# AON_WUC register map
Vendor: Texas Instruments
Peripheral module from a debugger description file (folder CC26x0R2F).
Registers are 32-bit, access per field, reset 0x0 unless marked. A register's access mark holds for its fields unless they carry their own. Offsets are as the file gives them; lines under a group give offsets from that group; [hi:lo] are bit positions; {n}, {i} and the like mark numbered series; 'fields as' and 'values as' point back to an identical list; <NAME> marks a mode.

## AON_WUC — This component control the Wakeup controller residing in the AON domain. Note: This module is only supporting 32 bit ReadWrite access from MCU
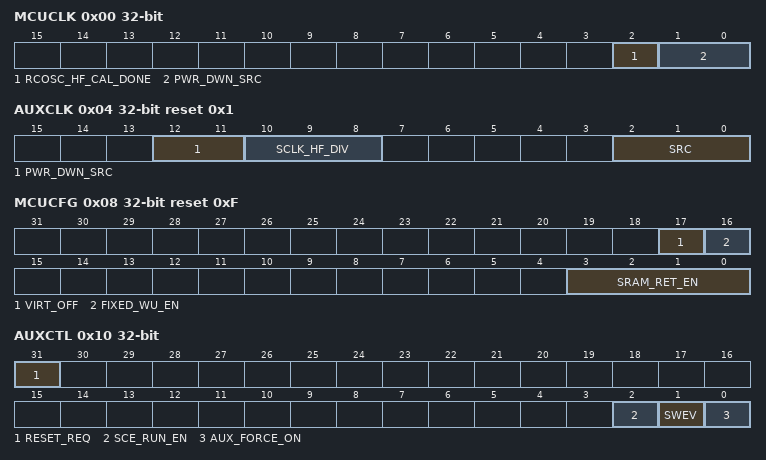
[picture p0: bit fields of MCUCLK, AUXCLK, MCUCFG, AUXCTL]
0x00 MCUCLK — MCU Clock Management This register contains bitfields related to the MCU clock.
  [2] RCOSC_HF_CAL_DONE rw — MCU bootcode will set this bit when RCOSC_HF is calibrated. The FLASH can not be used until this bit is set. 1: RCOSC_HF is calibrated to 48 MHz, allowing FLASH to power up. 0: RCOSC_HF is not yet calibrated, ie FLASH must not assume that the SCLK_HF is safe
  [1:0] PWR_DWN_SRC rw — Controls the clock source for the entire MCU domain while MCU is requesting powerdown. When MCU requests powerdown with SCLK_HF as source, then WUC will switch over to this clock source during powerdown, and automatically switch back to SCLK_HF when MCU is no longer requesting powerdown and system is back in active mode.
    1=SCLK_LF (Use SCLK_LF in Powerdown); 0=NONE (No clock in Powerdown)
0x04 AUXCLK reset 0x1 — AUX Clock Management This register contains bitfields that are relevant for setting up the clock to the AUX domain.
  [12:11] PWR_DWN_SRC rw — When AUX requests powerdown with SCLK_HF as source, then WUC will switch over to this clock source during powerdown, and automatically switch back to SCLK_HF when AUX system is back in active mode
    values as MCUCLK.PWR_DWN_SRC
  [10:8] SCLK_HF_DIV rw — Select the AUX clock divider for SCLK_HF NB: It is not supported to change the AUX clock divider while SCLK_HF is active source for AUX
    7=DIV256 (Divide by 256); 6=DIV128 (Divide by 128); 5=DIV64 (Divide by 64); 4=DIV32 (Divide by 32); 3=DIV16 (Divide by 16); 2=DIV8 (Divide by 8); 1=DIV4 (Divide by 4); 0=DIV2 (Divide by 2)
  [2:0] SRC rw — Selects the clock source for AUX: NB: Switching the clock source is guaranteed to be glitchless
    4=SCLK_LF (LF Clock (SCLK_LF)); 1=SCLK_HF (HF Clock (SCLK_HF))
0x08 MCUCFG reset 0xF — MCU Configuration This register contains power management related bitfields for the MCU domain.
  [17] VIRT_OFF rw — Internal. Only to be used through TI provided API.
  [16] FIXED_WU_EN rw — Internal. Only to be used through TI provided API.
  [3:0] SRAM_RET_EN rw — MCU SRAM is partitioned into 4 banks . This register controls which of the banks that has retention during MCU power off
    15=RET_FULL (Retention on for all banks (SRAM:BANK0, SRAM:BANK1 ,SRAM:BANK2 and SRAM:BANK3)); 7=RET_LEVEL3 (Retention on for SRAM:BANK0, SRAM:BANK1 and SRAM:BANK2); 3=RET_LEVEL2 (Retention on for SRAM:BANK0 and SRAM:BANK1); 1=RET_LEVEL1 (Retention on for SRAM:BANK0); 0=RET_NONE (Retention is disabled)
0x0C AUXCFG rw reset 0x1 — AUX Configuration This register contains power management related signals for the AUX domain.
  [0] RAM_RET_EN — This bit controls retention mode for the AUX_RAM:BANK0: 0: Retention is disabled 1: Retention is enabled NB: If retention is disabled, the AUX_RAM will be powered off when it would otherwise be put in retention mode
0x10 AUXCTL — AUX Control This register contains events and control signals for the AUX domain.
  [31] RESET_REQ rw — Reset request for AUX. Writing 1 to this register will assert reset to AUX. The reset will be held until the bit is cleared again. 0: AUX reset pin will be deasserted 1: AUX reset pin will be asserted
  [2] SCE_RUN_EN rw — Enables (1) or disables (0) AUX_SCE execution. AUX_SCE execution will begin when AUX Domain is powered and either this or AUX_SCE:CTL.CLK_EN is set. Setting this bit will assure that AUX_SCE execution starts as soon as AUX power domain is woken up. ( AUX_SCE:CTL.CLK_EN will be reset to 0 if AUX power domain has been off) 0: AUX_SCE execution will be disabled if AUX_SCE:CTL.CLK_EN is 0 1: AUX_SCE execution is enabled.
  [1] SWEV rw — Writing 1 sets the software event to the AUX domain, which can be read through AUX_WUC:WUEVFLAGS.AON_SW. This event is normally cleared by AUX_SCE through the AUX_WUC:WUEVCLR.AON_SW. It can also be cleared by writing 0 to this register. Reading 0 means that there is no outstanding software event for AUX. Note that it can take up to 1,5 SCLK_LF clock cycles to clear the event from AUX.
  [0] AUX_FORCE_ON rw — Forces the AUX domain into active mode, overriding the requests from AUX_WUC:PWROFFREQ, AUX_WUC:PWRDWNREQ and AUX_WUC:MCUBUSCTL. Note that an ongoing AUX_WUC:PWROFFREQ will complete before this bit will set the AUX domain into active mode. MCU must set this bit in order to access the AUX peripherals. The AUX domain status can be read from PWRSTAT.AUX_PD_ON 0: AUX is allowed to Power Off, Power Down or Disconnect. 1: AUX Power OFF, Power Down or Disconnect requests will be overruled
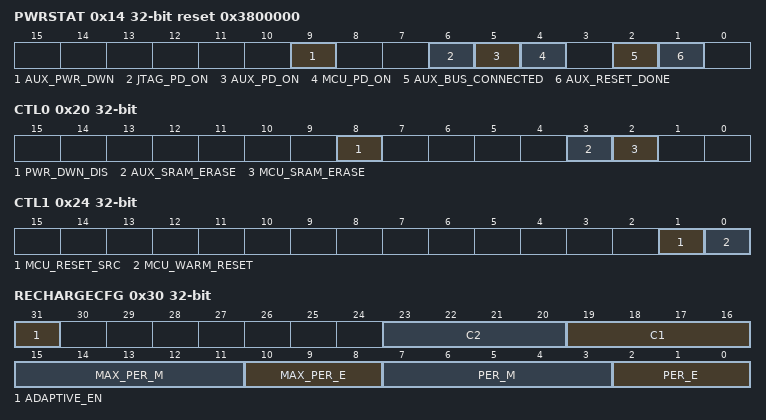
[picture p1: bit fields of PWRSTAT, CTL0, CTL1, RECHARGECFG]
0x14 PWRSTAT reset 0x3800000 — Power Status This register is used to monitor various power management related signals in AON. Most signals are for test, calibration and debug purpose only, and others can be used to detect that AUX or JTAG domains are powered up.
  [9] AUX_PWR_DWN ro — Indicates the AUX powerdown state when AUX domain is powered up. 0: Active mode 1: AUX Powerdown request has been granted
  [6] JTAG_PD_ON ro — Indicates JTAG power state: 0: JTAG is powered off 1: JTAG is powered on
  [5] AUX_PD_ON ro — Indicates AUX power state: 0: AUX is not ready for use ( may be powered off or in power state transition ) 1: AUX is powered on, connected to bus and ready for use,
  [4] MCU_PD_ON ro — Indicates MCU power state: 0: MCU Power sequencing is not yet finalized and MCU_AONIF registers may not be reliable 1: MCU Power sequencing is finalized and all MCU_AONIF registers are reliable
  [2] AUX_BUS_CONNECTED ro — Indicates that AUX Bus is connected: 0: AUX bus is not connected 1: AUX bus is connected ( idle_ack = 0 )
  [1] AUX_RESET_DONE ro — Indicates Reset Done from AUX: 0: AUX is being reset 1: AUX reset is released
0x18 SHUTDOWN rw — Shutdown Control This register contains bitfields required for entering shutdown mode
  [0] EN — Writing a 1 to this bit forces a shutdown request to be registered and all I/O values to be latched - in the PAD ring, possibly enabling I/O wakeup. Writing 0 will cancel a registered shutdown request and open th I/O latches residing in the PAD ring. A registered shutdown request takes effect the next time power down conditions exists. At this time, the will not enter Powerdown mode, but instead it will turn off all internal powersupplies, effectively putting the device into Shutdown mode.
0x20 CTL0 — Control 0 This register contains various chip level control and debug bitfields.
  [8] PWR_DWN_DIS rw — Controls whether MCU and AUX requesting to be powered off will enable a transition to powerdown: 0: Enabled 1: Disabled
  [3] AUX_SRAM_ERASE wo — Internal. Only to be used through TI provided API.
  [2] MCU_SRAM_ERASE wo — Internal. Only to be used through TI provided API.
0x24 CTL1 rw — Control 1 This register contains various chip level control and debug bitfields.
  [1] MCU_RESET_SRC — Indicates source of last MCU Voltage Domain warm reset request: 0: MCU SW reset 1: JTAG reset This bit can only be cleared by writing a 1 to it
  [0] MCU_WARM_RESET — Indicates type of last MCU Voltage Domain reset: 0: Last MCU reset was not a warm reset 1: Last MCU reset was a warm reset (requested from MCU or JTAG as indicated in MCU_RESET_SRC) This bit can only be cleared by writing a 1 to it
0x30 RECHARGECFG — Recharge Controller Configuration This register sets all relevant patameters for controlling the recharge algorithm.
  [31] ADAPTIVE_EN rw — Enable adaptive recharge Note: Recharge can be turned completely of by setting MAX_PER_E=7 and MAX_PER_M=31 and this bitfield to 0
  [23:20] C2 rw — Gain factor for adaptive recharge algorithm period_new=period * ( 1+/-(2^-C1+2^-C2) ) Valid values for C2 is 2 to 10 Note: Rounding may cause adaptive recharge not to start for very small values of both Gain and Initial period. Criteria for algorithm to start is MAX(PERIOD*2^-C1,PERIOD*2^-C2) >= 1
  [19:16] C1 rw — Gain factor for adaptive recharge algorithm period_new=period * ( 1+/-(2^-C1+2^-C2) ) Valid values for C1 is 1 to 10 Note: Rounding may cause adaptive recharge not to start for very small values of both Gain and Initial period. Criteria for algorithm to start is MAX(PERIOD*2^-C1,PERIOD*2^-C2) >= 1
  [15:11] MAX_PER_M rw — This register defines the maximum period that the recharge algorithm can take, i.e. it defines the maximum number of cycles between 2 recharges. The maximum number of cycles is specified with a 5 bit mantissa and 3 bit exponent: MAXCYCLES=(MAX_PER_M*16+15)*2^MAX_PER_E This field sets the mantissa of MAXCYCLES
  [10:8] MAX_PER_E rw — This register defines the maximum period that the recharge algorithm can take, i.e. it defines the maximum number of cycles between 2 recharges. The maximum number of cycles is specified with a 5 bit mantissa and 3 bit exponent: MAXCYCLES=(MAX_PER_M*16+15)*2^MAX_PER_E This field sets the exponent MAXCYCLES
  [7:3] PER_M rw — Number of 32 KHz clocks between activation of recharge controller For recharge algorithm, PERIOD is the initial period when entering powerdown mode. The adaptive recharge algorithm will not change this register PERIOD will effectively be a 16 bit value coded in a 5 bit mantissa and 3 bit exponent: This field sets the Mantissa of the Period. PERIOD=(PER_M*16+15)*2^PER_E
  [2:0] PER_E rw — Number of 32 KHz clocks between activation of recharge controller For recharge algorithm, PERIOD is the initial period when entering powerdown mode. The adaptive recharge algorithm will not change this register PERIOD will effectively be a 16 bit value coded in a 5 bit mantissa and 3 bit exponent: This field sets the Exponent of the Period. PERIOD=(PER_M*16+15)*2^PER_E
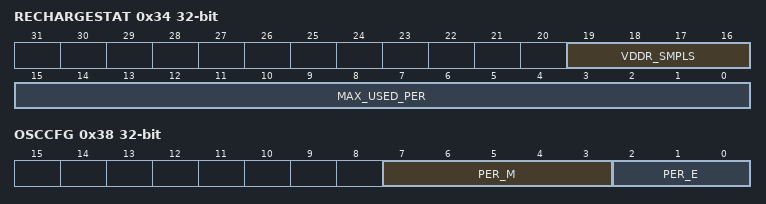
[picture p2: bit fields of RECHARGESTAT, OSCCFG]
0x34 RECHARGESTAT — Recharge Controller Status This register controls various status registers which are updated during recharge. The register is mostly intended for test and debug.
  [19:16] VDDR_SMPLS ro — The last 4 VDDR samples, bit 0 being the newest. The register is being updated in every recharge period with a shift left, and bit 0 is updated with the last VDDR sample, ie a 1 is shiftet in in case VDDR > VDDR_threshold just before recharge starts. Otherwise a 0 will be shifted in.
  [15:0] MAX_USED_PER rw — The maximum value of recharge period seen with VDDR>threshold. The VDDR voltage is compared against the threshold voltage at just before each recharge. If VDDR is above threshold, MAX_USED_PER is updated with max ( current recharge peride; MAX_USED_PER ) This way MAX_USED_PER can track the recharge period where VDDR is decharged to the threshold value. We can therefore use the value as an indication of the leakage current during recharge. This bitfield is cleared to 0 when writing this register.
0x38 OSCCFG — Oscillator Configuration This register sets the period for Amplitude compensation requests sent to the oscillator control system. The amplitude compensations is only applicable when XOSC_HF is running in low power mode.
  [7:3] PER_M rw — Number of 32 KHz clocks between oscillator amplitude calibrations. When this counter expires, an oscillator amplitude compensation is triggered immediately in Active mode. When this counter expires in Powerdown mode an internal flag is set such that the amplitude compensation is postponed until the next recharge occurs. The Period will effectively be a 16 bit value coded in a 5 bit mantissa and 3 bit exponent PERIOD=(PER_M*16+15)*2^PER_E This field sets the mantissa Note: Oscillator amplitude calibration is turned of when both this bitfield and PER_E are set to 0
  [2:0] PER_E rw — Number of 32 KHz clocks between oscillator amplitude calibrations. When this counter expires, an oscillator amplitude compensation is triggered immediately in Active mode. When this counter expires in Powerdown mode an internal flag is set such that the amplitude compensation is postponed until the next recharge occurs. The Period will effectively be a 16 bit value coded in a 5 bit mantissa and 3 bit exponent PERIOD=(PER_M*16+15)*2^PER_E This field sets the exponent Note: Oscillator amplitude calibration is turned of when both PER_M and this bitfield are set to 0
0x40 JTAGCFG reset 0x100 — JTAG Configuration This register contains control for configuration of the JTAG domain,- hereunder access permissions for each TAP.
  [8] JTAG_PD_FORCE_ON rw — Controls JTAG PowerDomain power state: 0: Controlled exclusively by debug subsystem. (JTAG Powerdomain will be powered off unless a debugger is attached) 1: JTAG Power Domain is forced on, independent of debug subsystem. NB: The reset value causes JTAG Power Domain to be powered on by default. Software must clear this bit to turn off the JTAG Power Domain
0x44 JTAGUSERCODE rw reset 0xB99A02F — JTAG USERCODE Boot code copies the JTAG USERCODE to this register from where it is forwarded to the debug subsystem.
  [31:0] USER_CODE — 32-bit JTAG USERCODE register feeding main JTAG TAP NB: This field can be locked
